# EFR32MG24A121F1536GM48 register map
Vendor: Silicon Labs; Series: EFR32; File version: B
Registers are 32-bit, read-write, reset 0x0 unless marked. A register's access mark holds for its fields unless they carry their own. Offsets are from the block's base; [hi:lo] are bit positions; {n}, {i} and the like mark numbered series.

## SCRATCHPAD_NS — SCRATCHPAD_NS Registers
Base 0x50000000
Same registers: SCRATCHPAD_S 0x40000000
0x00 SREG0 — Used for SIMCTRL Pointer in Verification Environment
  [31:0] SCRATCH — Scratch Pad Register
0x04 SREG1 — Used for SIMCTRL Data Access in Verification Environment
  [31:0] SCRATCH

## SEMAILBOX_NS_HOST — SEMAILBOX_NS_HOST Registers
Base 0x5C000000
Same registers: SEMAILBOX_S_HOST 0x4C000000
0x00 FIFO — A write access to any address in this area will be mapped to the TX FIFO (only for the payload). A read access to any address in this area will be mapped to the RX FIFO (only for the payload). Using an address range (16 x 32-bit) rather than one single address mapped to the FIFO allows using incremental bursts.
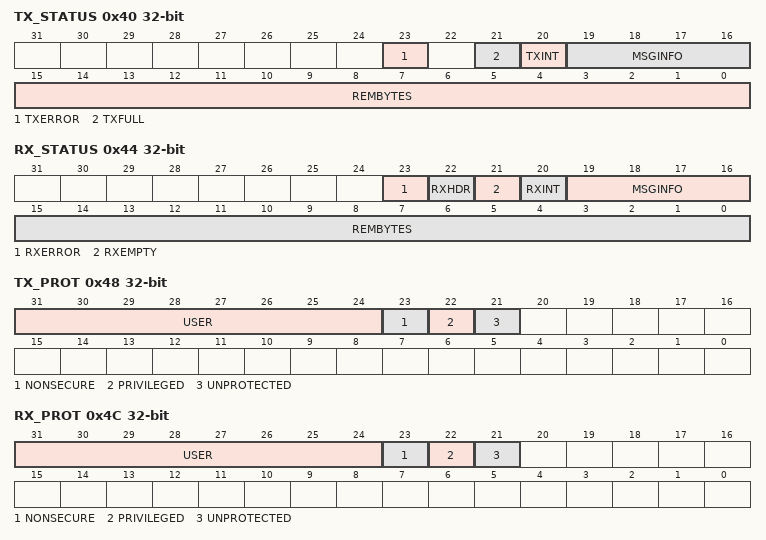
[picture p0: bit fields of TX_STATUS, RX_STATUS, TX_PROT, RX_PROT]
0x40 TX_STATUS ro
  [23] TXERROR, [21] TXFULL, [20] TXINT, [19:16] MSGINFO, [15:0] REMBYTES
0x44 RX_STATUS ro
  [23] RXERROR, [22] RXHDR, [21] RXEMPTY, [20] RXINT, [19:16] MSGINFO, [15:0] REMBYTES
0x48 TX_PROT ro — TX Protection register.
  [31:24] USER, [23] NONSECURE, [22] PRIVILEGED, [21] UNPROTECTED
0x4C RX_PROT ro — RX Protection register.
  [31:24] USER, [23] NONSECURE, [22] PRIVILEGED, [21] UNPROTECTED
0x50 TX_HEADER wo — A write access to this register will be mapped to the TX FIFO (only for header).
  [31:0] TXHEADER
0x54 RX_HEADER ro — A read access to this register will be mapped to the RX FIFO (only for the header).
  [31:0] RXHEADER
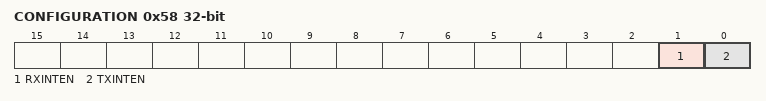
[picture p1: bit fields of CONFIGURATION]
0x58 CONFIGURATION
  [1] RXINTEN, [0] TXINTEN

## SMU_NS_CFGNS — SMU_NS_CFGNS Registers
Base 0x5400C000
Same registers: SMU_S_CFGNS 0x4400C000
0x04 NSSTATUS ro
  [0] SMUNSLOCK
    0=UNLOCKED; 1=LOCKED
0x08 NSLOCK wo
  [23:0] SMUNSLOCKKEY
    0xACCE55=UNLOCK (Unlocks Registers)
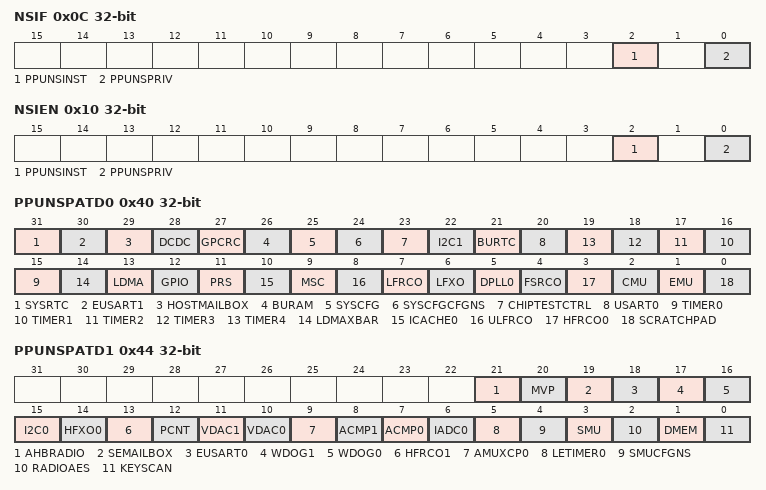
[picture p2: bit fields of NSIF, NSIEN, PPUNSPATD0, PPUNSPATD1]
0x0C NSIF
  [2] PPUNSINST — PPUNS Instruction Interrupt Flag
  [0] PPUNSPRIV — PPUNS Privilege Interrupt Flag
0x10 NSIEN
  [2] PPUNSINST — PPUNS Instruction Interrupt Enable
  [0] PPUNSPRIV — PPUNS Privilege Interrupt Enable
0x40 PPUNSPATD0 — Set peripheral bits to 1 to mark as privileged access only
  [31] SYSRTC — SYSRTC Privileged Access
  [30] EUSART1 — EUSART1 Privileged Access
  [29] HOSTMAILBOX — HOSTMAILBOX Privileged Access
  [28] DCDC — DCDC Privileged Access
  [27] GPCRC — GPCRC Privileged Access
  [26] BURAM — BURAM Privileged Access
  [25] SYSCFG — SYSCFG Privileged Access
  [24] SYSCFGCFGNS — SYSCFGCFGNS Privileged Access
  [23] CHIPTESTCTRL — CHIPTESTCTRL Privileged Access
  [22] I2C1 — I2C1 Privileged Access
  [21] BURTC — BURTC Privileged Access
  [20] USART0 — USART0 Privileged Access
  [n+15] TIMER{n} (n=0..4) — TIMER{n} Privileged Access
  [14] LDMAXBAR — LDMAXBAR Privileged Access
  [13] LDMA — LDMA Privileged Access
  [12] GPIO — GPIO Privileged Access
  [11] PRS — PRS Privileged Access
  [10] ICACHE0 — ICACHE0 Privileged Access
  [9] MSC — MSC Privileged Access
  [8] ULFRCO — ULFRCO Privileged Access
  [7] LFRCO — LFRCO Privileged Access
  [6] LFXO — LFXO Privileged Access
  [5] DPLL0 — DPLL0 Privileged Access
  [4] FSRCO — FSRCO Privileged Access
  [3] HFRCO0 — HFRCO0 Privileged Access
  [2] CMU — CMU Privileged Access
  [1] EMU — EMU Privileged Access
  [0] SCRATCHPAD — SCRATCHPAD Privileged Access
0x44 PPUNSPATD1 — Set peripheral bits to 1 to mark as privileged access only
  [21] AHBRADIO — AHBRADIO Privileged Access
  [20] MVP — MVP Privileged Access
  [19] SEMAILBOX — SEMAILBOX Privileged Access
  [18] EUSART0 — EUSART0 Privileged Access
  [17] WDOG1 — WDOG1 Privileged Access
  [16] WDOG0 — WDOG0 Privileged Access
  [15] I2C0 — I2C0 Privileged Access
  [14] HFXO0 — HFXO0 Privileged Access
  [13] HFRCO1 — HFRCO1 Privileged Access
  [12] PCNT — PCNT Privileged Access
  [11] VDAC1 — VDAC1 Privileged Access
  [10] VDAC0 — VDAC0 Privileged Access
  [9] AMUXCP0 — AMUXCP0 Privileged Access
  [8] ACMP1 — ACMP1 Privileged Access
  [7] ACMP0 — ACMP0 Privileged Access
  [6] IADC0 — IADC0 Privileged Access
  [5] LETIMER0 — LETIMER0 Privileged Access
  [4] SMUCFGNS — SMUCFGNS Privileged Access
  [3] SMU — SMU Privileged Access
  [2] RADIOAES — RADIOAES Privileged Access
  [1] DMEM — DMEM Privileged Access
  [0] KEYSCAN — KEYSCAN Privileged Access
0x140 PPUNSFS ro
  [7:0] PPUFSPERIPHID — Peripheral I
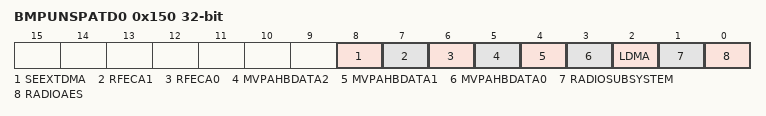
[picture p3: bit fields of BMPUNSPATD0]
0x150 BMPUNSPATD0
  [8] SEEXTDMA — SEEXTDMA privileged mode
  [7] RFECA1 — RFECA1 privileged mode
  [6] RFECA0 — RFECA0 privileged mode
  [5] MVPAHBDATA2 — MVPAHBDATA2 privileged mode
  [4] MVPAHBDATA1 — MVPAHBDATA1 privileged mode
  [3] MVPAHBDATA0 — MVPAHBDATA0 privileged mode
  [2] LDMA — MCU LDMA privileged mode
  [1] RADIOSUBSYSTEM — RADIO subsystem manager privileged mode
  [0] RADIOAES — RADIO AES DMA privileged mode
